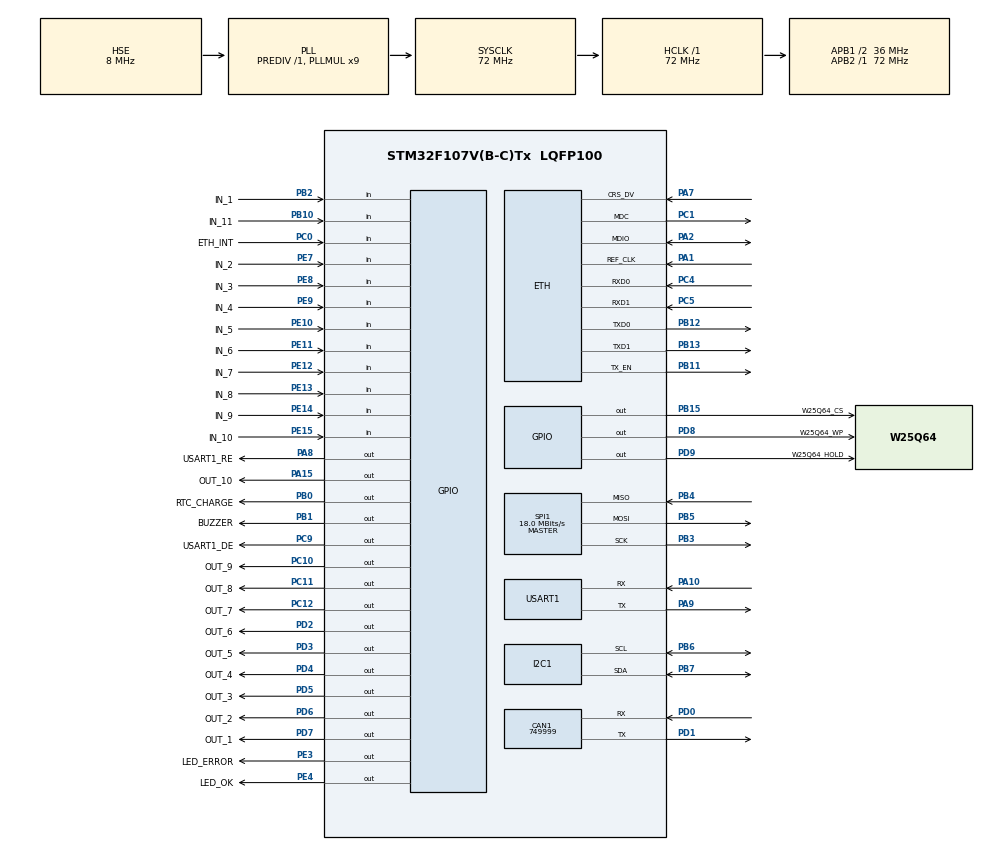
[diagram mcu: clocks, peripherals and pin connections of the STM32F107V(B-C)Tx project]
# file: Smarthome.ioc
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CAN1.CalculateBaudRate=749999
CAN1.CalculateTimeBit=1333
CAN1.CalculateTimeQuantum=444.44444444444446
ETH.AutoNegotiation=ETH_AUTONEGOTIATION_ENABLE
ETH.MACAddr=00\:80\:E1\:00\:00\:01
ETH.MediaInterface=ETH_MEDIA_INTERFACE_RMII
ETH.PHY_DUPLEX_STATUS=0x0010
ETH.PHY_ISFR=0x001D
ETH.PHY_ISFR_INT4=0x0010
ETH.PHY_SPEED_STATUS=0x0004
ETH.PHY_SR=0x1F
ETH.PhyAddress=0
ETH.Speed=ETH_SPEED_100M
FREERTOS.Tasks01=defaultTask,0,512,StartDefaultTask,Default,NULL,Dynamic,NULL,NULL;TCPServer,1,512,TCPServerTask,As external,NULL,Dynamic,NULL,NULL;CLU,0,512,CLUTask,As external,NULL,Dynamic,NULL,NULL
FREERTOS.configMINIMAL_STACK_SIZE=512
FREERTOS.configTOTAL_HEAP_SIZE=15000
FREERTOS.configUSE_NEWLIB_REENTRANT=1
I2C1.I2C_Mode=I2C_Fast
LWIP.GATEWAY_ADDRESS=192.168.000.001
LWIP.IP_ADDRESS=192.168.000.023
LWIP.LWIP_DHCP=1
LWIP.LWIP_NETIF_LINK_CALLBACK=1
LWIP.MEM_SIZE=10*1024
LWIP.NETIF_DEBUG=LWIP_DBG_OFF
LWIP.NETMASK_ADDRESS=255.255.255.000
LWIP.RTOS_USE_NEWLIB_REENTRANT=1
LWIP.Version=v2.0.3_Cube
Mcu.Family=STM32F1
Mcu.Name=STM32F107V(B-C)Tx
Mcu.Package=LQFP100
NVIC.ETH_IRQn=true\:5\:0\:false\:false\:true\:true\:false\:true\:true
NVIC.I2C1_ER_IRQn=true\:5\:0\:false\:false\:true\:true\:true\:true\:true
NVIC.I2C1_EV_IRQn=true\:5\:0\:false\:false\:true\:true\:true\:true\:true
NVIC.PriorityGroup=NVIC_PRIORITYGROUP_4
NVIC.TIM7_IRQn=true\:15\:0\:false\:false\:true\:false\:false\:true\:true
NVIC.TimeBase=TIM7_IRQn
NVIC.TimeBaseIP=TIM7
OSC_IN.Mode=HSE-External-Oscillator
OSC_IN.Signal=RCC_OSC_IN
OSC_OUT.Mode=HSE-External-Oscillator
OSC_OUT.Signal=RCC_OSC_OUT
PA1.Mode=RMII
PA1.Signal=ETH_REF_CLK
PA10.Mode=Asynchronous
PA10.Signal=USART1_RX
PA13.Mode=Serial_Wire
PA13.Signal=SYS_JTMS-SWDIO
PA14.Mode=Serial_Wire
PA14.Signal=SYS_JTCK-SWCLK
PA15.GPIO_Label=OUT_10
PA15.Signal=GPIO_Output
PA2.Mode=RMII
PA2.Signal=ETH_MDIO
PA7.Mode=RMII
PA7.Signal=ETH_CRS_DV
PA8.GPIO_Label=USART1_RE
PA8.Signal=GPIO_Output
PA9.Mode=Asynchronous
PA9.Signal=USART1_TX
PB0.GPIO_Label=RTC_CHARGE
PB0.Signal=GPIO_Output
PB1.GPIO_Label=BUZZER
PB1.Signal=GPIO_Output
PB10.GPIO_Label=IN_11
PB10.Signal=GPIO_Input
PB11.Mode=RMII
PB11.Signal=ETH_TX_EN
PB12.Mode=RMII
PB12.Signal=ETH_TXD0
PB13.Mode=RMII
PB13.Signal=ETH_TXD1
PB15.GPIO_Label=W25Q64_CS
PB15.Signal=GPIO_Output
PB2.GPIO_Label=IN_1
PB2.Signal=GPIO_Input
PB3.Mode=Full_Duplex_Master
PB3.Signal=SPI1_SCK
PB4.Mode=Full_Duplex_Master
PB4.Signal=SPI1_MISO
PB5.Mode=Full_Duplex_Master
PB5.Signal=SPI1_MOSI
PB6.Mode=I2C
PB6.Signal=I2C1_SCL
PB7.Mode=I2C
PB7.Signal=I2C1_SDA
PC0.GPIO_Label=ETH_INT
PC0.GPIO_PuPd=GPIO_NOPULL
PC0.Signal=GPIO_Input
PC1.Mode=RMII
PC1.Signal=ETH_MDC
PC10.GPIO_Label=OUT_9
PC10.Signal=GPIO_Output
PC11.GPIO_Label=OUT_8
PC11.Signal=GPIO_Output
PC12.GPIO_Label=OUT_7
PC12.Signal=GPIO_Output
PC4.Mode=RMII
PC4.Signal=ETH_RXD0
PC5.Mode=RMII
PC5.Signal=ETH_RXD1
PC9.GPIO_Label=USART1_DE
PC9.Signal=GPIO_Output
PD0.Mode=CAN_Activate
PD0.Signal=CAN1_RX
PD1.Mode=CAN_Activate
PD1.Signal=CAN1_TX
PD2.GPIO_Label=OUT_6
PD2.Signal=GPIO_Output
PD3.GPIO_Label=OUT_5
PD3.Signal=GPIO_Output
PD4.GPIO_Label=OUT_4
PD4.Signal=GPIO_Output
PD5.GPIO_Label=OUT_3
PD5.Signal=GPIO_Output
PD6.GPIO_Label=OUT_2
PD6.Signal=GPIO_Output
PD7.GPIO_Label=OUT_1
PD7.Signal=GPIO_Output
PD8.GPIO_Label=W25Q64_WP
PD8.Signal=GPIO_Output
PD9.GPIO_Label=W25Q64_HOLD
PD9.Signal=GPIO_Output
PE10.GPIO_Label=IN_5
PE10.Signal=GPIO_Input
PE11.GPIO_Label=IN_6
PE11.Signal=GPIO_Input
PE12.GPIO_Label=IN_7
PE12.Signal=GPIO_Input
PE13.GPIO_Label=IN_8
PE13.Signal=GPIO_Input
PE14.GPIO_Label=IN_9
PE14.Signal=GPIO_Input
PE15.GPIO_Label=IN_10
PE15.Signal=GPIO_Input
PE3.GPIO_Label=LED_ERROR
PE3.Signal=GPIO_Output
PE4.GPIO_Label=LED_OK
PE4.Signal=GPIO_Output
PE7.GPIO_Label=IN_2
PE7.Signal=GPIO_Input
PE8.GPIO_Label=IN_3
PE8.Signal=GPIO_Input
PE9.GPIO_Label=IN_4
PE9.Signal=GPIO_Input
ProjectManager.HeapSize=0x200
ProjectManager.StackSize=0x400
ProjectManager.TargetToolchain=STM32CubeIDE
RCC.AHBFreq_Value=72000000
RCC.APB1CLKDivider=RCC_HCLK_DIV2
RCC.APB1Freq_Value=36000000
RCC.APB1TimFreq_Value=72000000
RCC.APB2Freq_Value=72000000
RCC.APB2TimFreq_Value=72000000
RCC.HCLKFreq_Value=72000000
RCC.PLLMUL=RCC_PLL_MUL9
RCC.PLLSourceVirtual=RCC_PLLSOURCE_HSE
RCC.SYSCLKFreq_VALUE=72000000
RCC.SYSCLKSource=RCC_SYSCLKSOURCE_PLLCLK
RCC.USBFreq_Value=48000000
SPI1.BaudRatePrescaler=SPI_BAUDRATEPRESCALER_4
SPI1.CalculateBaudRate=18.0 MBits/s
SPI1.Direction=SPI_DIRECTION_2LINES
SPI1.Mode=SPI_MODE_MASTER
SPI1.VirtualType=VM_MASTER
USART1.VirtualMode=VM_ASYNC
VP_FREERTOS_VS_CMSIS_V1.Mode=CMSIS_V1
VP_LWIP_VS_Enabled.Mode=Enabled
VP_SYS_VS_tim7.Mode=TIM7
board=custom

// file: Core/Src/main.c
/* USER CODE BEGIN Header */
/**
  ******************************************************************************
  * @file           : main.c
  * @brief          : Main program body
  ******************************************************************************
  * @attention
  *
  * Copyright (c) 2023 STMicroelectronics.
  * All rights reserved.
  *
  * This software is licensed under terms that can be found in the LICENSE file
  * in the root directory of this software component.
  * If no LICENSE file comes with this software, it is provided AS-IS.
  *
  ******************************************************************************
  */
/* USER CODE END Header */
#include "main.h"
#include "cmsis_os.h"
#include "can.h"
#include "i2c.h"
#include "lwip.h"
#include "spi.h"
#include "usart.h"
#include "gpio.h"

/* USER CODE BEGIN Includes */
#include "../Smarthome/TCPServer/tcpserver.h"
/* USER CODE END Includes */

void SystemClock_Config(void);
void MX_FREERTOS_Init(void);

int main(void)
{

  /* MCU Configuration--------------------------------------------------------*/

  /* Reset of all peripherals, Initializes the Flash interface and the Systick. */
  HAL_Init();

  /* Configure the system clock */
  SystemClock_Config();

  /* Initialize all configured peripherals */
  MX_GPIO_Init();
  MX_I2C1_Init();
  MX_CAN1_Init();
  MX_SPI1_Init();
  MX_USART1_UART_Init();

  /* Call init function for freertos objects (in freertos.c) */
  MX_FREERTOS_Init();

  /* Start scheduler */
  osKernelStart();
  /* We should never get here as control is now taken by the scheduler */
  /* Infinite loop */
  while (1)
  {

  }
}

void SystemClock_Config(void)
{
  RCC_OscInitTypeDef RCC_OscInitStruct = {0};
  RCC_ClkInitTypeDef RCC_ClkInitStruct = {0};

  /** Initializes the RCC Oscillators according to the specified parameters
  * in the RCC_OscInitTypeDef structure.
  */
  RCC_OscInitStruct.OscillatorType = RCC_OSCILLATORTYPE_HSE;
  RCC_OscInitStruct.HSEState = RCC_HSE_ON;
  RCC_OscInitStruct.HSEPredivValue = RCC_HSE_PREDIV_DIV1;
  RCC_OscInitStruct.HSIState = RCC_HSI_ON;
  RCC_OscInitStruct.Prediv1Source = RCC_PREDIV1_SOURCE_HSE;
  RCC_OscInitStruct.PLL.PLLState = RCC_PLL_ON;
  RCC_OscInitStruct.PLL.PLLSource = RCC_PLLSOURCE_HSE;
  RCC_OscInitStruct.PLL.PLLMUL = RCC_PLL_MUL9;
  RCC_OscInitStruct.PLL2.PLL2State = RCC_PLL_NONE;
  if (HAL_RCC_OscConfig(&RCC_OscInitStruct) != HAL_OK)
  {
    Error_Handler();
  }

  /** Initializes the CPU, AHB and APB buses clocks
  */
  RCC_ClkInitStruct.ClockType = RCC_CLOCKTYPE_HCLK|RCC_CLOCKTYPE_SYSCLK
                              |RCC_CLOCKTYPE_PCLK1|RCC_CLOCKTYPE_PCLK2;
  RCC_ClkInitStruct.SYSCLKSource = RCC_SYSCLKSOURCE_PLLCLK;
  RCC_ClkInitStruct.AHBCLKDivider = RCC_SYSCLK_DIV1;
  RCC_ClkInitStruct.APB1CLKDivider = RCC_HCLK_DIV2;
  RCC_ClkInitStruct.APB2CLKDivider = RCC_HCLK_DIV1;

  if (HAL_RCC_ClockConfig(&RCC_ClkInitStruct, FLASH_LATENCY_2) != HAL_OK)
  {
    Error_Handler();
  }

  /** Configure the Systick interrupt time
  */
  __HAL_RCC_PLLI2S_ENABLE();
}

void HAL_TIM_PeriodElapsedCallback(TIM_HandleTypeDef *htim)
{
  if (htim->Instance == TIM7) {
    HAL_IncTick();
  }
}

void Error_Handler(void)
{
  __disable_irq();
  while (1)
  {
  }
}

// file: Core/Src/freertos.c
/* USER CODE BEGIN Header */
/**
  ******************************************************************************
  * File Name          : freertos.c
  * Description        : Code for freertos applications
  ******************************************************************************
  * @attention
  *
  * Copyright (c) 2023 STMicroelectronics.
  * All rights reserved.
  *
  * This software is licensed under terms that can be found in the LICENSE file
  * in the root directory of this software component.
  * If no LICENSE file comes with this software, it is provided AS-IS.
  *
  ******************************************************************************
  */
/* USER CODE END Header */

#include "FreeRTOS.h"
#include "task.h"
#include "main.h"
#include "cmsis_os.h"

/* USER CODE BEGIN Variables */
int sem;
/* USER CODE END Variables */
osThreadId defaultTaskHandle;
osThreadId TCPServerHandle;
osThreadId CLUHandle;

void StartDefaultTask(void const * argument);
extern void TCPServerTask(void const * argument);
extern void CLUTask(void const * argument);

extern void MX_LWIP_Init(void);
void MX_FREERTOS_Init(void); /* (MISRA C 2004 rule 8.1) */

/* GetIdleTaskMemory prototype (linked to static allocation support) */
void vApplicationGetIdleTaskMemory( StaticTask_t **ppxIdleTaskTCBBuffer, StackType_t **ppxIdleTaskStackBuffer, uint32_t *pulIdleTaskStackSize );

/* USER CODE BEGIN GET_IDLE_TASK_MEMORY */
static StaticTask_t xIdleTaskTCBBuffer;
static StackType_t xIdleStack[configMINIMAL_STACK_SIZE];

void vApplicationGetIdleTaskMemory( StaticTask_t **ppxIdleTaskTCBBuffer, StackType_t **ppxIdleTaskStackBuffer, uint32_t *pulIdleTaskStackSize )
{
  *ppxIdleTaskTCBBuffer = &xIdleTaskTCBBuffer;
  *ppxIdleTaskStackBuffer = &xIdleStack[0];
  *pulIdleTaskStackSize = configMINIMAL_STACK_SIZE;
  /* place for user code */
}
/* USER CODE END GET_IDLE_TASK_MEMORY */

void MX_FREERTOS_Init(void) {

  /* Create the thread(s) */
  /* definition and creation of defaultTask */
  osThreadDef(defaultTask, StartDefaultTask, osPriorityNormal, 0, 512);
  defaultTaskHandle = osThreadCreate(osThread(defaultTask), NULL);

  /* definition and creation of TCPServer */
  osThreadDef(TCPServer, TCPServerTask, osPriorityAboveNormal, 0, 512);
  TCPServerHandle = osThreadCreate(osThread(TCPServer), NULL);

  /* definition and creation of CLU */
  osThreadDef(CLU, CLUTask, osPriorityNormal, 0, 512);
  CLUHandle = osThreadCreate(osThread(CLU), NULL);

}

void StartDefaultTask(void const * argument)
{
  /* init code for LWIP */
  MX_LWIP_Init();
  /* USER CODE BEGIN StartDefaultTask */
  sem = 1;
  /* Infinite loop */
  for(;;)
  {
    osDelay(1000);
  }
  /* USER CODE END StartDefaultTask */
}
